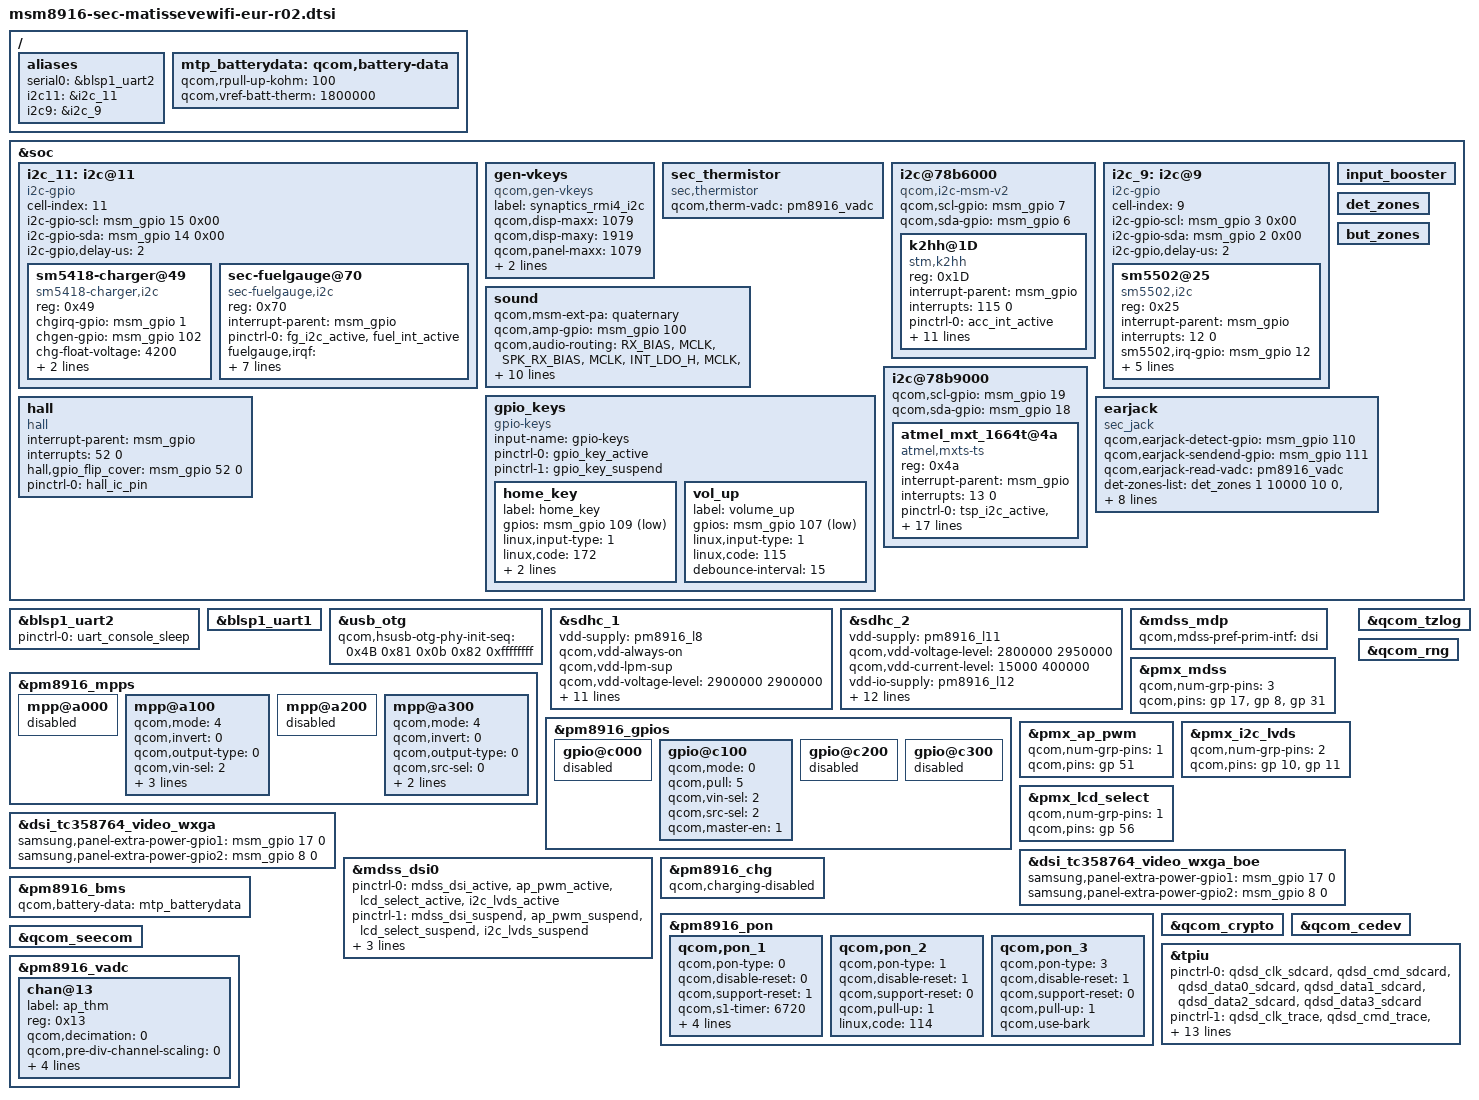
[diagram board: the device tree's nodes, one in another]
/* Copyright (c) 2014, The Linux Foundation. All rights reserved.
 *
 * This program is free software; you can redistribute it and/or modify
 * it under the terms of the GNU General Public License version 2 and
 * only version 2 as published by the Free Software Foundation.
 *
 * This program is distributed in the hope that it will be useful,
 * but WITHOUT ANY WARRANTY; without even the implied warranty of
 * MERCHANTABILITY or FITNESS FOR A PARTICULAR PURPOSE.  See the
 * GNU General Public License for more details.
 */

#include "msm8916.dtsi"
#include "msm8916-camera-sensor-matisse.dtsi"
#include "msm8916-pinctrl-sec-matissevewifi-eur-r02.dtsi"
#include "msm8916-sec-matissevewifi-eur-battery-r00.dtsi" 
#include "../../../../../../drivers/video/msm/mdss/samsung/TC358764_LTL101AL06_KTD3156/dsi_panel_TC358764_LTL101AL06_KTD3156.dtsi"
#include "../../../../../../drivers/video/msm/mdss/samsung/TC358764_LTL101AL06_KTD3156/dsi_panel_TC358764_BP101WX1_KTD3156.dtsi"
/ {
	aliases {
		serial0 = &blsp1_uart2;
		i2c11 = &i2c_11;
		i2c9 = &i2c_9;
	};
};

&soc {

       i2c_11:i2c@11 {
		cell-index = <11>;
		compatible = "i2c-gpio";
		i2c-gpio-scl = <&msm_gpio 15 0x00>;
		i2c-gpio-sda = <&msm_gpio 14 0x00>;
		i2c-gpio,delay-us = <2>;
		#address-cells = <1>;
		#size-cells = <0>;

		sm5418-charger@49{
			compatible = "sm5418-charger,i2c";
			reg = <0x49>;
			chgirq-gpio = <&msm_gpio 1 0>;
			chgen-gpio = <&msm_gpio 102 0>;
			chg-float-voltage = <4200>;
			chg-irq-attr = <0x00000002>;
			pinctrl-names = "default";
			pinctrl-0 = <&charger_en_active &ta_int_n_default>;
		};

		sec-fuelgauge@70{
			compatible = "sec-fuelgauge,i2c";
			reg = <0x70>;
			interrupt-parent = <&msm_gpio>;
			pinctrl-names = "default";
			pinctrl-0 = <&fg_i2c_active &fuel_int_active>;
			fuelgauge,irqf = "IRQF_TRIGGER_FALLING + IRQF_ONESHOT + IRQF_NO_SUSPEND";
			fuelgauge,fuel_int = <&msm_gpio 121 0x1>;
			fuelgauge,capacity_max = <1000>;
			fuelgauge,capacity_max_margin = <50>;
			fuelgauge,capacity_min = <0>;
			fuelgauge,capacity_calculation_type = <0x17>;
			fuelgauge,fuel_alert_soc = <1>;
		};
	};

	gen-vkeys {
		compatible = "qcom,gen-vkeys";
		label = "synaptics_rmi4_i2c";
		qcom,disp-maxx = <1079>;
		qcom,disp-maxy = <1919>;
		qcom,panel-maxx = <1079>;
		qcom,panel-maxy = <2084>;
		qcom,key-codes = <158 139 172 217>;
	};

	sec_thermistor {
		compatible = "sec,thermistor";
		qcom,therm-vadc = <&pm8916_vadc>;
	};

/* GPIO_0 is used by LCD
	i2c@78ba000 {
		nfc-nci@e {
			compatible = "qcom,nfc-nci";
			reg = <0x0e>;
			qcom,irq-gpio = <&msm_gpio 21 0x00>;
			qcom,dis-gpio = <&msm_gpio 20 0x00>;
			qcom,clk-src = "BBCLK2";
			qcom,clk-en-gpio = <&msm_gpio 0 0x00>;
			interrupt-parent = <&msm_gpio>;
			interrupts = <21 0>;
			interrupt-names = "nfc_irq";
			pinctrl-names = "nfc_active","nfc_suspend";
			pinctrl-0 = <&nfc_int_active &nfc_disable_active>;
			pinctrl-1 = <&nfc_int_suspend &nfc_disable_suspend>;
			qcom,clk-gpio = <&pm8916_gpios 2 0>;
			clocks = <&clock_rpm clk_bb_clk2_pin>;
			clock-names = "ref_clk";
		};
	};
*/
	i2c@78b6000 { /* BLSP1 QUP2 */
		compatible = "qcom,i2c-msm-v2";
		qcom,scl-gpio = <&msm_gpio 7 0>;
		qcom,sda-gpio = <&msm_gpio 6 0>;
		k2hh@1D {
			compatible = "stm,k2hh";
			reg = <0x1D>;
			interrupt-parent = <&msm_gpio>;
			interrupts = <115 0>;
			pinctrl-names = "default";
			pinctrl-0 = <&acc_int_active>;
			stm,irq_gpio = <&msm_gpio 115 0x00>;
			stm,vio-supply = <&pm8916_l5>;
			stm,vdd-supply = <&pm8916_l17>;
			stm,axis_map_x = <0>;
			stm,axis_map_y = <1>;
			stm,axis_map_z = <2>;
			stm,negate_x = <1>;
			stm,negate_y = <1>;
			stm,negate_z = <1>;
			stm,poll_interval = <100>;
			stm,min_interval = <2>;
		};
	};

	i2c_9:i2c@9 { /*SM5502 GPIO-I2C*/
		cell-index = <9>;
		compatible = "i2c-gpio";
		i2c-gpio-scl = <&msm_gpio 3 0x00>;
		i2c-gpio-sda = <&msm_gpio 2 0x00>;
		i2c-gpio,delay-us = <2>;
		#address-cells = <1>;
		#size-cells = <0>;

		sm5502@25{
			compatible = "sm5502,i2c";
			reg = <0x25>;
			interrupt-parent = <&msm_gpio>;
			interrupts= <12 0>;
			sm5502,irq-gpio = <&msm_gpio 12 0x00>;
			sm5502,gpio-sda = <&msm_gpio 2 0x00>;
			sm5502,gpio-scl = <&msm_gpio 3 0x00>;
			sm5502,uarton-gpio = <&msm_gpio 113 0x00>;
			pinctrl-names = "sm5502_i2c_active","sm5502_i2c_suspend";
			pinctrl-0 = <&muic_i2c_active &muic_int_pin>;
			pinctrl-1 = <&muic_i2c_suspend &muic_int_pin>;
		};
	};


	/* Over-riding model specific changes */
	sound {
		qcom,msm-ext-pa = "quaternary";
		qcom,amp-gpio = <&msm_gpio 100 0x0>;
		qcom,audio-routing =
			"RX_BIAS", "MCLK",
			"SPK_RX_BIAS", "MCLK",
			"INT_LDO_H", "MCLK",
			"MIC BIAS External", "Handset Mic",
			"MIC BIAS External", "Secondary Mic",
			"AMIC1", "MIC BIAS External",
			"AMIC2", "Headset Mic",
			"AMIC3", "MIC BIAS External";
		pinctrl-names = "cdc_lines_act",
				"cdc_lines_sus",
				"cdc_lines_quat_ext_act",
				"cdc_lines_quat_ext_sus";
		pinctrl-0 = <&cdc_pdm_lines_act>;
		pinctrl-1 = <&cdc_pdm_lines_sus>;
		pinctrl-2 = <&cdc_pdm_lines_act &ext_cdc_tlmm_lines_act>;
		pinctrl-3 = <&cdc_pdm_lines_sus &ext_cdc_tlmm_lines_sus>;
	};
};

&blsp1_uart2 {
	status = "ok";
	pinctrl-names = "default";
	pinctrl-0 = <&uart_console_sleep>;
};

&soc {
	gpio_keys {
		compatible = "gpio-keys";
		input-name = "gpio-keys";
		pinctrl-names = "tlmm_gpio_key_active","tlmm_gpio_key_suspend";
		pinctrl-0 = <&gpio_key_active>;
		pinctrl-1 = <&gpio_key_suspend>;

		home_key {
			label = "home_key";
			gpios = <&msm_gpio 109 0x1>;
			linux,input-type = <1>;
			linux,code = <172>;
			gpio-key,wakeup;
			debounce-interval = <15>;
		};

		vol_up {
			label = "volume_up";
			gpios = <&msm_gpio 107 0x1>;
			linux,input-type = <1>;
			linux,code = <115>;
			debounce-interval = <15>;
		};
	};
	input_booster {
		status = "okay";
	};

	hall {
		status = "okay";
		compatible = "hall";
		interrupt-parent = <&msm_gpio>;
		interrupts = <52 0>;
		hall,gpio_flip_cover = <&msm_gpio 52 0>;
		pinctrl-names = "pmx_hall_ic_pin";
		pinctrl-0 = <&hall_ic_pin>;
	};

/*	i2c_10:i2c@10 {
		cell-index = <10>;
		compatible = "i2c-gpio";
		i2c-gpio-scl = <&msm_gpio 17  0x00>;
		i2c-gpio-sda = <&msm_gpio 16 0x00>;
		i2c-gpio,delay-us = <1>;
		#address-cells = <1>;
		#size-cells = <0>;

		tc360@20 {
			compatible = "coreriver,coreriver-tkey";
			reg = <0x20>;
			interrupt-parent = <&msm_gpio>;
			interrupts = <98 0>;
			pinctrl-names = "tkey_gpio_active","tkey_gpio_suspend";
			pinctrl-0 = <&tkey_i2c_active>;
			pinctrl-1 = <&tkey_i2c_active>;

			//coreriver,vcc_en_ldo_name = "max77826_ldo15";
			coreriver,vcc_en-gpio = <&msm_gpio 97 0x00>;
			//coreriver,vdd_led_ldo_name = "max77826_ldo12";
			coreriver,scl-gpio = <&msm_gpio 17 0x00>;
			coreriver,sda-gpio = <&msm_gpio 16 0x00>;
			coreriver,irq-gpio = <&msm_gpio  98 0x00>;
			coreriver,tkey-keycodes = <254 158>;
			coreriver,i2c-pull-up = <1>;
			coreriver,gpio_seperated = <1>;
			//coreriver,firm-up;

		};
	};*/
	i2c@78b9000 { /* BLSP1 QUP5 */
		qcom,scl-gpio = <&msm_gpio 19 0>;
		qcom,sda-gpio = <&msm_gpio 18 0>;
                status = "okay";
			atmel_mxt_1664t@4a {
				compatible = "atmel,mxts-ts";
                                reg = <0x4a>; /*slave address*/
                                interrupt-parent = <&msm_gpio>;
                                interrupts = <13 0>; /* Touch int gpio */
				pinctrl-names = "tsp_gpio_active", "tsp_gpio_suspend";
				pinctrl-0 = <&tsp_i2c_active &tsp_irq_gpio_active &tsp_en_active &tsp_vendor_active>;
				pinctrl-1 = <&tsp_i2c_suspend &tsp_irq_gpio_suspend &tsp_en_suspend &tsp_vendor_suspend>;
                                mxts,tsppwr_en = <&msm_gpio 73 0x1>;
                                mxts,tsppwr_en1 = <&msm_gpio 98 0x1>;
                                mxts,vendor1 = <&msm_gpio 55 0x1>;
                                /*vcc_en-supply = <&pm8941_l10>;*/
                                mxts,irq-gpio = <&msm_gpio 13 0x00>; /*TSP IRQ GPIO */
                                mxts,rst = <&msm_gpio 114 0x1>;
                                mxts,i2c-pull-up = <1>;
                                mxts,num_x = <27>; /*num of x-node*/
                                mxts,num_y = <44>; /*num of y node*/
                                mxts,max_x = <4095>; /*max x*/
                                mxts,max_y = <4095>; /*max y*/
                                mxts,tsp_coord = <27 44 4095 4095>;
                                mxts,pname = "SM-T530"; /*Matisse SM-T535*/
		};
	};

	det_zones: det_zones {
		#list-det-cells = <4>;
	};

	but_zones: but_zones {
		#list-but-cells = <3>;
	};

	earjack {
		compatible = "sec_jack";
		qcom,earjack-detect-gpio = <&msm_gpio 110 0x0>;
		qcom,earjack-sendend-gpio = <&msm_gpio 111 0x0>;
		qcom,earjack-read-vadc = <&pm8916_vadc>;

		det-zones-list = <&det_zones 1 10000 10 0>,
				 <&det_zones 940 10000 10 0>,
				 <&det_zones 1901 10000 10 1>,
				 <&det_zones 9999 10000 10 1>;
		but-zones-list = <&but_zones 0 1 320>,
				 <&but_zones 1 321 450>,
				 <&but_zones 2 451 850>;
		mpp-channel-scaling = <2 1 1>;
		pinctrl-names = "earjack_gpio_active","earjack_gpio_suspend";
		pinctrl-0 = <&earjack_det_act &earjack_switch_act>;
		pinctrl-1 = <&earjack_det_sus &earjack_switch_sus>;
	};
};

&blsp1_uart1 {
	status = "ok";
};

&usb_otg {
	qcom,hsusb-otg-phy-init-seq =
					<0x4B 0x81 0x0b 0x82 0xffffffff>;
};

&sdhc_1 {
	vdd-supply = <&pm8916_l8>;
	qcom,vdd-always-on;
	qcom,vdd-lpm-sup;
	qcom,vdd-voltage-level = <2900000 2900000>;
	qcom,vdd-current-level = <200 400000>;

	vdd-io-supply = <&pm8916_l5>;
	qcom,vdd-io-always-on;
	qcom,vdd-io-lpm-sup;
	qcom,vdd-io-voltage-level = <1800000 1800000>;
	qcom,vdd-io-current-level = <200 60000>;

	pinctrl-names = "active", "sleep";
	pinctrl-0 = <&sdc1_clk_on &sdc1_cmd_on &sdc1_data_on>;
	pinctrl-1 = <&sdc1_clk_off &sdc1_cmd_off &sdc1_data_off>;

	qcom,nonremovable;

	status = "ok";
};

&sdhc_2 {
	vdd-supply = <&pm8916_l11>;
	qcom,vdd-voltage-level = <2800000 2950000>;
	qcom,vdd-current-level = <15000 400000>;

	vdd-io-supply = <&pm8916_l12>;
	qcom,vdd-io-voltage-level = <1800000 2950000>;
	qcom,vdd-io-current-level = <200 50000>;

	pinctrl-names = "active", "sleep";
	pinctrl-0 = <&sdc2_clk_on &sdc2_cmd_on &sdc2_data_on &sdc2_cd_on>;
	pinctrl-1 = <&sdc2_clk_off &sdc2_cmd_off &sdc2_data_off &sdc2_cd_off>;

	#address-cells = <0>;
	interrupt-parent = <&sdhc_2>;
	interrupts = <0 1 2>;
	#interrupt-cells = <1>;
	interrupt-map-mask = <0xffffffff>;
	interrupt-map = <0 &intc 0 125 0
			1 &intc 0 221 0
			2 &msm_gpio 38 0>;
	interrupt-names = "hc_irq", "pwr_irq", "status_irq";
	cd-gpios = <&msm_gpio 38 0x1>;

	status = "ok";
};

&pm8916_mpps {
	mpp@a000 { /* MPP 1 */
		/* VDD_PX */
		status = "disabled";
	};

	mpp@a100 { /* MPP 2 */
		status = "ok";
		qcom,mode = <4>; // AIN input
		qcom,invert = <0>; //No Invert
		qcom,output-type = <0>; //CMOS
		qcom,vin-sel = <2>; //PM8971_S3 1.8v
		qcom,src-sel = <0>; //MPP Constant
		qcom,ain-route = <1>; // QPNP_PIN_AIN_AMUX_CH6 = 1 for MPP2
		qcom,master-en = <1>; // Function constant
	};

	mpp@a200 { /* MPP 3 */
		/* VREF DAC */
		status = "disabled";
	};

	mpp@a300 { /* MPP 4 */
		status = "ok";
		qcom,mode = <4>;	/* AIN input */
		qcom,invert = <0>;	/* No Invert */
		qcom,output-type = <0>;	/* CMOS */
		qcom,src-sel = <0>;	/* MPP Constant */
		qcom,ain-route = <3>;	/* QPNP_PIN_AIN_AMUX_CH8 = 3 for MPP4 */
		qcom,master-en = <1>;	/* Function constant */
	};
};

&pm8916_gpios {
	gpio@c000 { /* GPIO 1 */
		/* Battery UICC Alarm */
		status = "disabled";
	};

	gpio@c100 { /* GPIO 2 */
		/* NFC_CLK_REQ */
		qcom,mode = <0>; /* QPNP_PIN_MODE_DIG_IN */
		qcom,pull = <5>; /* QPNP_PIN_PULL_NO */
		qcom,vin-sel = <2>; /* QPNP_PIN_VIN2 */
		qcom,src-sel = <2>; /* QPNP_PIN_SEL_FUNC_1 */
		qcom,master-en = <1>;
	};

	gpio@c200 { /* GPIO 3 */
		/* External regulator control for WTR */
		status = "disabled";
	};

	gpio@c300 { /* GPIO 4 */
		/* External regulator control for APC */
		status = "disabled";
	};
};

&mdss_mdp {
	qcom,mdss-pref-prim-intf = "dsi";
};

&pmx_mdss {
	qcom,num-grp-pins = <3>;
	qcom,pins = <&gp 17>, <&gp 8>, <&gp 31>;
};

&pmx_ap_pwm {
	qcom,num-grp-pins = <1>;
	qcom,pins = <&gp 51>;
};


&pmx_i2c_lvds {
	qcom,num-grp-pins = <2>;
	qcom,pins = <&gp 10>, <&gp 11>;
};

&pmx_lcd_select {
	qcom,num-grp-pins = <1>;
	qcom,pins = <&gp 56>;
};

&dsi_tc358764_video_wxga {
	samsung,panel-extra-power-gpio1 = <&msm_gpio 17 0>;  /*lvds*/
	samsung,panel-extra-power-gpio2 = <&msm_gpio 8 0>; /*lcd*/
};


&dsi_tc358764_video_wxga_boe {
	samsung,panel-extra-power-gpio1 = <&msm_gpio 17 0>;  /*lvds*/
	samsung,panel-extra-power-gpio2 = <&msm_gpio 8 0>; /*lcd*/
};

&mdss_dsi0 {
	pinctrl-names = "mdss_default", "mdss_sleep";
	pinctrl-0 = <&mdss_dsi_active &ap_pwm_active &lcd_select_active &i2c_lvds_active>;
	pinctrl-1 = <&mdss_dsi_suspend &ap_pwm_suspend &lcd_select_suspend &i2c_lvds_suspend>;
	qcom,platform-reset-gpio = <&msm_gpio 31 0>;
	qcom,platform-backlight-pwm-gpio = <&msm_gpio 51 0>;
	qcom,platform-lcd-select-gpio = <&msm_gpio 56 0>;
};

&pm8916_chg {
	status = "ok";
	qcom,charging-disabled;
};

/ {
	mtp_batterydata: qcom,battery-data {
		qcom,rpull-up-kohm = <100>;
		qcom,vref-batt-therm = <1800000>;

		#include "batterydata-palladium.dtsi"
	};
};

&pm8916_bms {
	status = "ok";
	qcom,battery-data = <&mtp_batterydata>;
};

&pm8916_pon {
	qcom,pon_1 {
		qcom,pon-type = <0>;
		qcom,disable-reset = <0>;
		qcom,support-reset = <1>;
		qcom,s1-timer = <6720>;
		qcom,s2-timer = <1000>;
		qcom,s2-type = <8>;
		qcom,pull-up = <1>;
		linux,code = <116>;
	};

	qcom,pon_2 {
		qcom,pon-type = <1>;
		qcom,disable-reset = <1>;
		qcom,support-reset = <0>;
		qcom,pull-up = <1>;
		linux,code = <114>;
	};

	qcom,pon_3 {
		qcom,pon-type = <3>;
		qcom,disable-reset = <1>;
		qcom,support-reset = <0>;
		qcom,pull-up = <1>;
		qcom,use-bark;
	};
};

&qcom_tzlog {
	status = "okay";
};

&qcom_rng {
	status = "okay";
};

&qcom_crypto {
	status = "okay";
};

&qcom_cedev {
	status = "okay";
};

&qcom_seecom {
	status = "okay";
};

/* CoreSight */
&tpiu {
      pinctrl-names = "sdcard", "trace", "swduart",
		      "swdtrc", "jtag", "spmi";
       /* NIDnT */
      pinctrl-0 = <&qdsd_clk_sdcard &qdsd_cmd_sdcard
                  &qdsd_data0_sdcard &qdsd_data1_sdcard
                  &qdsd_data2_sdcard &qdsd_data3_sdcard>;
      pinctrl-1 = <&qdsd_clk_trace &qdsd_cmd_trace
                  &qdsd_data0_trace &qdsd_data1_trace
                  &qdsd_data2_trace &qdsd_data3_trace>;
      pinctrl-2 = <&qdsd_cmd_swduart &qdsd_data0_swduart
                  &qdsd_data1_swduart &qdsd_data2_swduart
                  &qdsd_data3_swduart>;
      pinctrl-3 = <&qdsd_clk_swdtrc &qdsd_cmd_swdtrc
                  &qdsd_data0_swdtrc &qdsd_data1_swdtrc
                  &qdsd_data2_swdtrc &qdsd_data3_swdtrc>;
      pinctrl-4 = <&qdsd_cmd_jtag &qdsd_data0_jtag
                  &qdsd_data1_jtag &qdsd_data2_jtag
                  &qdsd_data3_jtag>;
      pinctrl-5 = <&qdsd_clk_spmi &qdsd_cmd_spmi
                  &qdsd_data0_spmi &qdsd_data3_spmi>;
};
&pm8916_vadc {
	chan@13 {
		label = "ap_thm";
		reg = <0x13>;	/* channel 19 for MPP4 , 1:1scale */
		qcom,decimation = <0>;
		qcom,pre-div-channel-scaling = <0>;	/* 1:1scale */
		qcom,calibration-type = "ratiometric";
		qcom,scale-function = <1>;
		qcom,hw-settle-time = <2>;
		qcom,fast-avg-setup = <0>;
	};
};
